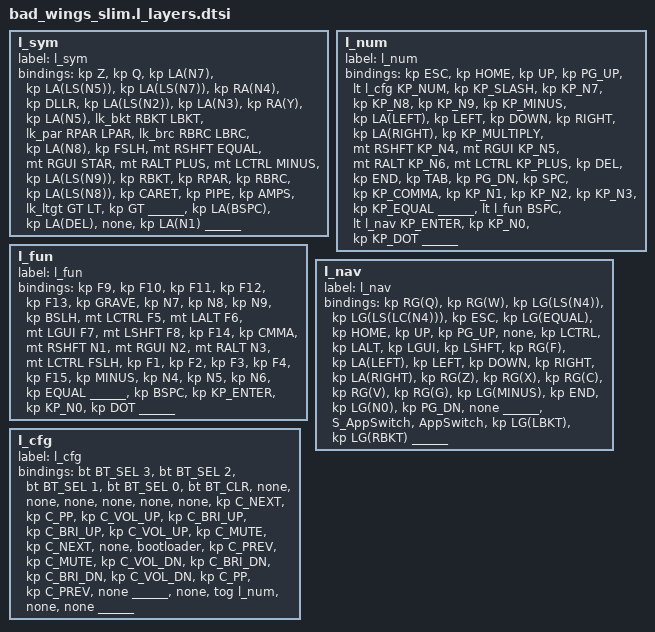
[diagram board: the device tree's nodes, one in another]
/*
 Building for a 34-36 key board
 */

//                                       Symbol & math (for Mac)
//  * left paired symbols are "linger keys" via hold taps. Tap for left, hold for pair with insertion point between
//╭────────────────────────────────────────────╮ ╭──────────────────────────────────────────╮
//|    Z   |    Q    |   ¶   |   †   |    ‡    | |   ¢   |    $   |    €   |    £   |   ¥   |
//|    §   |    [    |   (   |   {   |    •    | |   /   |    =   |    *   |    +   |   -   |
//|    ·   |    ]    |   )   |   }   |    °    | |   ^   |    |   |    &   |    <   |   >   |
//╰──────────────────╮       | dwdlt |  dwdr   | | &none |    ¡   |        ╭────────────────╯
//                   ╰─────────────────────────╯ ╰─────────────────────────╯
                l_sym {
                    label = "l_sym";
                    bindings = <
&kp Z &kp Q &kp LA(N7) &kp LA(LS(N5)) &kp LA(LS(N7))                   &kp RA(N4) &kp DLLR  &kp LA(LS(N2)) &kp LA(N3) &kp RA(Y)
&kp LA(N5)  &lk_bkt RBKT LBKT &lk_par RPAR LPAR &lk_brc RBRC LBRC &kp LA(N8) &kp FSLH &mt RSHFT EQUAL &mt RGUI STAR   &mt RALT PLUS  &mt LCTRL MINUS
&kp LA(LS(N9)) &kp RBKT &kp RPAR &kp RBRC &kp LA(LS(N8))                         &kp CARET  &kp PIPE  &kp AMPS     &lk_ltgt GT LT  &kp GT
                            ______ &kp LA(BSPC)   &kp LA(DEL)        &none      &kp LA(N1) ______
                    >;
                };

//                                          Nav & NumPad (standard)
//╭────────────────────────────────────────────╮ ╭────────────────────────────────────────╮
//|   ESC  |  HOME  |   UP   |  PG_UP |  NUM   | |    /   |   7   |   8   |   9   |   -   |
//|  Lword |  LEFT  |  DOWN  |   RGT  | Rword  | |    *   |  S/4  |  G/5  |  A/6  |  C/+  |
//|   DEL  |  END   |  TAB   |  PG_DN |  SPC   | |    ,   |   1   |   2   |   3   |   =   |
//╰─────────────────╮        |  BKSP  | ENTER  | |    0   |   .   |       ╭───────────────╯
//                  ╰──────────────────────────╯ ╰────────────────────────╯
                l_num {
                        label = "l_num"; //
                        bindings = <

&kp ESC      &kp HOME &kp UP    &kp PG_UP &lt l_cfg KP_NUM      &kp KP_SLASH    &kp KP_N7 &kp KP_N8 &kp KP_N9 &kp KP_MINUS
&kp LA(LEFT) &kp LEFT  &kp DOWN  &kp RIGHT  &kp LA(RIGHT) &kp KP_MULTIPLY &mt RSHFT KP_N4 &mt RGUI KP_N5 &mt RALT KP_N6 &mt LCTRL KP_PLUS
&kp DEL   &kp END &kp TAB &kp PG_DN  &kp SPC     &kp KP_COMMA    &kp KP_N1 &kp KP_N2 &kp KP_N3 &kp KP_EQUAL
                ______ &lt l_fun BSPC &lt l_nav KP_ENTER                &kp KP_N0  &kp KP_DOT ______
                        >;
                };

//                                         Fkey & Num Row (optimized)
//╭────────────────────────────────────────────╮ ╭───────────────────────────────────────╮
//|    F9   |  F10   |  F11   |  F12   |  F13  | |   `   |   7   |   8   |   9   |   \   |
//|   C/F5  |  A/F6  |  G/F7  |  S/F8  |  F14  | |   ,   |  S/1  |  G/2  |  A/3  |  C//  |
//|    F1   |   F2   |   F3   |   F4   |  F15  | |   -   |   4   |   5   |   6   |   =   |
//╰──────────────────╮        |  BKSP  |   DEL | |   0   |   .   |       ╭───────────────╯
//                   ╰─────────────────────────╯ ╰───────────────────────╯

                l_fun {
                        label = "l_fun";
                        bindings = <

&kp F9       &kp F10     &kp F11      &kp F12      &kp F13          &kp GRAVE &kp N7       &kp N8      &kp N9      &kp BSLH
&mt LCTRL F5 &mt LALT F6 &mt LGUI F7  &mt LSHFT F8 &kp F14          &kp CMMA  &mt RSHFT N1 &mt RGUI N2 &mt RALT N3 &mt LCTRL FSLH
&kp F1       &kp F2      &kp F3       &kp F4       &kp F15          &kp MINUS &kp N4       &kp N5      &kp N6      &kp EQUAL
                                ______ &kp BSPC     &kp KP_ENTER     &kp KP_N0    &kp DOT ______
                        >;
                };

//                                     shorcuts & Navigation
//╭────────────────────────────────────────────╮ ╭──────────────────────────────────────────╮
//|  close |   quit  | ScrCp | SelCp |   ESC   | | Zoom+ |  HOME  |   UP   |  PG_UP |       |
//|   ctrl |   alt   |  gui  |  shft |   Find  | | Lword |  LEFT  |  DOWN  |   RGT  | Rword |
//|  undo  |   cut   |  copy |  pste | findAgn | | Zoom- |   END  | Zreset |  PG_DN |  |
//╰──────────────────╮       | mute  |  APPSW  | |  back |  fwd   |        ╭────────────────╯
//                   ╰─────────────────────────╯ ╰─────────────────────────╯
                l_nav {
                    label = "l_nav";
                    bindings = <
&kp RG(Q) &kp RG(W) &kp LG(LS(N4)) &kp LG(LS(LC(N4))) &kp ESC  &kp LG(EQUAL) &kp HOME &kp UP     &kp PG_UP &none
&kp LCTRL  &kp LALT &kp LGUI &kp LSHFT   &kp RG(F)             &kp LA(LEFT)  &kp LEFT &kp DOWN   &kp RIGHT &kp LA(RIGHT)
&kp RG(Z)  &kp RG(X) &kp RG(C) &kp RG(V) &kp RG(G)             &kp LG(MINUS) &kp END  &kp LG(N0) &kp PG_DN &none
                        ______          &S_AppSwitch    &AppSwitch  &kp LG(LBKT)    &kp LG(RBKT) ______
                    >;
                };

//                                     Keyboard & System Settings
                l_cfg {
                        label = "l_cfg";
                        bindings = <
//&none &none &none &none &none &none &none &none &none &none &none &none
&bt BT_SEL 3 &bt BT_SEL 2 &bt BT_SEL 1 &bt BT_SEL 0 &bt BT_CLR      &none        &none        &none      &none        &none
&none        &kp C_NEXT   &kp C_PP     &kp C_VOL_UP &kp C_BRI_UP    &kp C_BRI_UP &kp C_VOL_UP &kp C_MUTE &kp C_NEXT &none
&bootloader  &kp C_PREV   &kp C_MUTE   &kp C_VOL_DN &kp C_BRI_DN    &kp C_BRI_DN &kp C_VOL_DN &kp C_PP   &kp C_PREV   &none
                                        ______ &none &tog l_num      &none   &none ______
                        >;
                };
